# A31G12x_series register map
Vendor: ABOV Semiconductor Co., Ltd.; Series: A31G12x_series; File version: 1.0
CPU: CM0PLUS r0p1, little endian, no MPU, no FPU, VTOR, 2 interrupt priority bits
Registers are 32-bit, read-write, reset 0x0 unless marked. A register's access mark holds for its fields unless they carry their own. Offsets are from the block's base; [hi:lo] are bit positions; {n}, {i} and the like mark numbered series.

## SCULV — LOW VOLTAGE INDICATOR(LVI) AND LOW VOLTAGE RESET(LVR)
Base 0x40005100
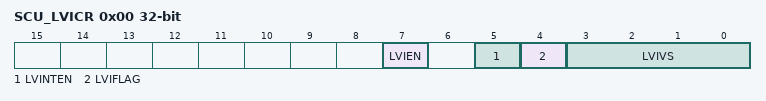
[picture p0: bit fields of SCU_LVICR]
0x00 SCU_LVICR — Low Voltage Indicator Control Register
  [7] LVIEN — LVI Enable bit
    0=DISABLE_LVI (Disable low voltage indicator); 1=ENABLE_LVI (Enable low voltage indicator)
  [5] LVINTEN — LVI Interrupt Enable bit
    0=DISABLE_LVI_INT (Disable low voltage indicator interrupt); 1=ENABLE_LVI_INT (Enable low voltage indicator interrupt)
  [4] LVIFLAG — LVI Interrupt Flag bit
    0=LVI_IF_CLR (No request occurred); 1=LVI_IF_SET (Request occurred, This bit is cleared to '0' when write '1'.)
  [3:0] LVIVS — LVI Voltage Selection bits
    3=1.88V; 4=2.00V; 5=2.13V; 6=2.28V; 7=2.46V; 8=2.67V; 9=3.04V; 10=3.20V; 11=3.55V; 12=3.75V; 13=3.99V; 14=4.25V; 15=4.55V
0x04 SCU_LVRCR — Low Voltage Reset Control Register
  [7:0] LVREN — LVR Enable bits
    85=DISABLE_LVR (Disable low voltage reset); 0=ENABLE_LVR (Enable low voltage reset)

## CFGOPT0 — CONFIGURE OPTION AREA
Base 0x1FFFF000
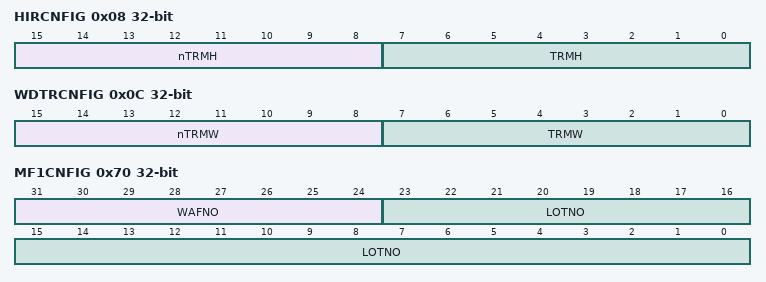
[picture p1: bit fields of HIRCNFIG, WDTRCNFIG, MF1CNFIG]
0x08 HIRCNFIG ro — Trim Value for High Frequency Internal RC Oscillator (HIRC)
  [15:8] nTRMH — Complement Value for TRMH[7:0]
  [7:0] TRMH — High Frequency Internal RC Oscillator Trimming Value.
0x0C WDTRCNFIG ro — Trim Value for Watch-dog Timer RC Oscillator (WDTRC)
  [15:8] nTRMW — Complement Value for TRMW[7:0]
  [7:0] TRMW — Watch-dog Timer RC Oscillator Trimming Value.
0x6C MF0CNFIG ro — Manufacture Information 0
  [31:0] XYCDN — X and Y Coordinates
0x70 MF1CNFIG ro — Manufacture Information 1
  [31:24] WAFNO — Wafer Number
  [23:0] LOTNO — Lot Number: LOTNO[55:32]
0x74 MF2CNFIG ro — Manufacture Information 2
  [31:0] LOTNO — Lot Number: LOTNO[31:0]
0x78 VAL0CNFIG ro reset 0x5661B396 — Validation 0 for System
  [31:0] VALID0 — Validation 0 Data for System
0x7C VAL1CNFIG ro reset 0x4461AB9A — Validation 1 for System
  [31:0] VALID1 — Validation 1 Data for System

## CFGOPT1 — CONFIGURE OPTION AREA
Base 0x1FFFF200
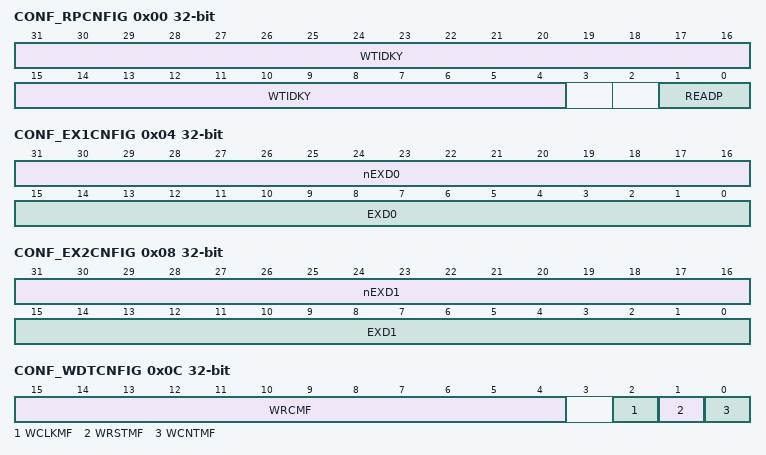
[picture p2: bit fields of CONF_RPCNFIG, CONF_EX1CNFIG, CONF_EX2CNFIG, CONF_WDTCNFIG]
0x00 CONF_RPCNFIG ro — Configuration for Read Protection. Notes: 1. The read protection level can be changed from lower level to higher level only. 2. The "Configure Option Page 1" can't be erased by page unit on "read protection level 1 and 2". 3. The configure option area may be read even if the "read protection" is on level 1 and 2. 4. A page unit erase/write except a bulk erase isn't executable by "Instruction from RAM" regardless of the FMWTP0 register on read protection level 2. 5. A page unit erase/write except a bulk erase isn't executable by "Debug" regardless of the FMWTP0 register on read protection level 1/2.
  [31:4] WTIDKY — Write Identification Key. These bits are the write key for "Read Protection". So, The WTIDKY[27:0] should be kept with the 0x69C8A27. Otherwise, the read protection will be on level 2.
  [1:0] READP — Read Protection for Flash Memory Area.
0x04 CONF_EX1CNFIG ro — Extra 1 for User Data
  [31:16] nEXD0 — Complement Value for EXD0[15:0]
  [15:0] EXD0 — Extra 0 for User Data
0x08 CONF_EX2CNFIG ro — Extra 2 for User Data
  [31:16] nEXD1 — Complement Value for EXD1[15:0]
  [15:0] EXD1 — Extra 1 for User Data
0x0C CONF_WDTCNFIG ro — Watch-dog Timer Configuration
  [15:4] WRCMF — Watch-dog Timer RC Oscillator Master Configuration 0x96D = The WDTRC oscillation is decided by the WDTRCEN of CLKSRCR register 0x2A7 = Master enable WDTRC but disabled at power-down mode Other values = Master enable WDTRC
  [2] WCLKMF — Watch-dog Timer Clock Selection Master Configuration
    0=SELECT_USING_WDTCLK (Watch-dog timer clock is selected by the WDTCLK of PPCLKSR register); 1=SELECT_WDTRC_ONLY (Master selection WDTRC for watch-dog timer clock)
  [1] WRSTMF — Watch-dog Timer Reset Enable Master Configuration
    0=ENABLE_WDT_RST_ONLY (Master enable WDT reset); 1=CONTROL_USING_RSTEN (Disable/Enable of WDT reset is decided by the RSTEN[5:0] of WDTCR register)
  [0] WCNTMF — Watch-dog Timer Counter Enable Master Configuration
    0=ENABLE_WDT_CNT_ONLY (Master enable WDT counter); 1=CONTROL_USING_CNTEN (Disable/Enable WDT counter is decided by the CNTEN[5:0] of WDTCR register)
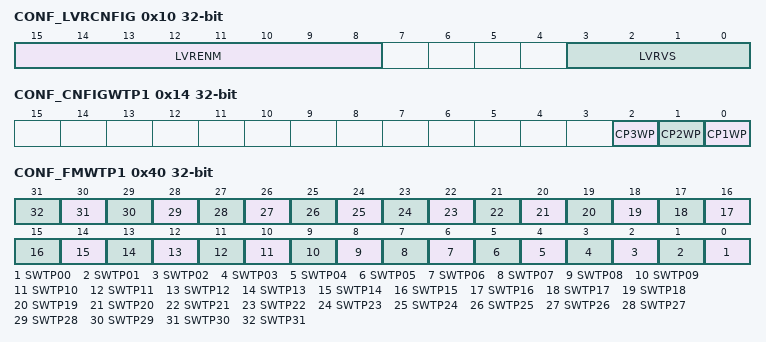
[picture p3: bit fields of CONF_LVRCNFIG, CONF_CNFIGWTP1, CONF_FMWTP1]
0x10 CONF_LVRCNFIG ro — Low Voltage Reset Configuration
  [15:8] LVRENM — LVR Reset Operation Control Master bits
  [3:0] LVRVS — LVR Voltage Selection bits
0x14 CONF_CNFIGWTP1 ro — Configure Option Page Erase/Write Protection 1. Note: The configure option page which is protected can't be erased by page unit.
  [2] CP3WP — Configure Option Page 3 Erase/Write Protection
  [1] CP2WP — Configure Option Page 2 Erase/Write Protection
  [0] CP1WP — Configure Option Page 1 Erase/Write Protection
0x40 CONF_FMWTP1 ro — Flash Memory Erase/Write Protection 0
  [n] SWTP{n:02} (n=0..31) — Sector {n:02} Flash Memory Erase/Write Protection bits

## CFGOPT2 — CONFIGURE OPTION AREA
Base 0x1FFFF400
Same registers: CFGOPT3 0x1FFFF600
0x00 USERDATAn ro — User Data Area 0
